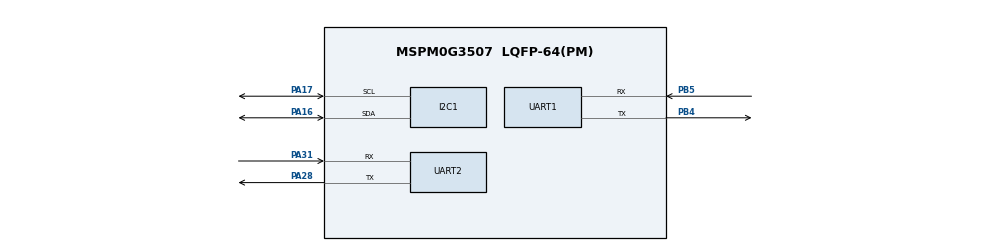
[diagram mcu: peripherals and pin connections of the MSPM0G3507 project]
/**
 * These arguments were used when this file was generated. They will be automatically applied on subsequent loads
 * via the GUI or CLI. Run CLI with '--help' for additional information on how to override these arguments.
 * @cliArgs --device "MSPM0G350X" --part "Default" --package "LQFP-64(PM)" --product "mspm0_sdk@2.05.01.00"
 * @v2CliArgs --device "MSPM0G3507" --package "LQFP-64(PM)" --product "mspm0_sdk@2.05.01.00"
 * @versions {"tool":"1.24.1+4189"}
 */

/**
 * Import the modules used in this configuration.
 */
const I2C     = scripting.addModule("/ti/driverlib/I2C", {}, false);
const I2C1    = I2C.addInstance();
const SYSCTL  = scripting.addModule("/ti/driverlib/SYSCTL");
const SYSTICK = scripting.addModule("/ti/driverlib/SYSTICK");
const TIMER   = scripting.addModule("/ti/driverlib/TIMER", {}, false);
const TIMER1  = TIMER.addInstance();
const UART    = scripting.addModule("/ti/driverlib/UART", {}, false);
const UART1   = UART.addInstance();
const UART2   = UART.addInstance();

/**
 * Write custom configuration values to the imported modules.
 */
const gate7  = system.clockTree["MFCLKGATE"];
gate7.enable = true;

I2C1.$name                           = "I2C_0";
I2C1.basicEnableController           = true;
I2C1.basicControllerStandardBusSpeed = "Fast";
I2C1.peripheral.sdaPin.$assign       = "PA16";
I2C1.peripheral.sclPin.$assign       = "PA17";
I2C1.sdaPinConfig.$name              = "ti_driverlib_gpio_GPIOPinGeneric4";
I2C1.sclPinConfig.$name              = "ti_driverlib_gpio_GPIOPinGeneric5";

const Board = scripting.addModule("/ti/driverlib/Board", {}, false);

SYSCTL.forceDefaultClkConfig = true;
SYSCTL.clockTreeEn           = true;

SYSTICK.periodEnable      = true;
SYSTICK.period            = 32000;
SYSTICK.interruptEnable   = true;
SYSTICK.interruptPriority = "0";
SYSTICK.systickEnable     = true;

TIMER1.$name              = "TIMER_gimbal";
TIMER1.timerClkDiv        = 8;
TIMER1.timerClkPrescale   = 100;
TIMER1.timerMode          = "PERIODIC";
TIMER1.timerPeriod        = "0.005";
TIMER1.timerStartTimer    = true;
TIMER1.interrupts         = ["ZERO"];
TIMER1.peripheral.$assign = "TIMA1";

UART1.$name                            = "UART_1";
UART1.uartClkSrc                       = "MFCLK";
UART1.targetBaudRate                   = 115200;
UART1.enabledInterrupts                = ["RX","TX"];
UART1.peripheral.$assign               = "UART1";
UART1.peripheral.rxPin.$assign         = "PB5";
UART1.peripheral.txPin.$assign         = "PB4";
UART1.txPinConfig.$name                = "ti_driverlib_gpio_GPIOPinGeneric0";
UART1.txPinConfig.direction            = scripting.forceWrite("OUTPUT");
UART1.txPinConfig.hideOutputInversion  = scripting.forceWrite(false);
UART1.txPinConfig.onlyInternalResistor = scripting.forceWrite(false);
UART1.txPinConfig.passedPeripheralType = scripting.forceWrite("Digital");
UART1.rxPinConfig.$name                = "ti_driverlib_gpio_GPIOPinGeneric1";
UART1.rxPinConfig.hideOutputInversion  = scripting.forceWrite(false);
UART1.rxPinConfig.onlyInternalResistor = scripting.forceWrite(false);
UART1.rxPinConfig.passedPeripheralType = scripting.forceWrite("Digital");

UART2.$name                            = "UART_0";
UART2.uartClkSrc                       = "MFCLK";
UART2.targetBaudRate                   = 115200;
UART2.enabledInterrupts                = ["RX","TX"];
UART2.peripheral.rxPin.$assign         = "PA31";
UART2.peripheral.txPin.$assign         = "PA28";
UART2.txPinConfig.$name                = "ti_driverlib_gpio_GPIOPinGeneric2";
UART2.txPinConfig.direction            = scripting.forceWrite("OUTPUT");
UART2.txPinConfig.hideOutputInversion  = scripting.forceWrite(false);
UART2.txPinConfig.onlyInternalResistor = scripting.forceWrite(false);
UART2.txPinConfig.passedPeripheralType = scripting.forceWrite("Digital");
UART2.rxPinConfig.$name                = "ti_driverlib_gpio_GPIOPinGeneric3";
UART2.rxPinConfig.hideOutputInversion  = scripting.forceWrite(false);
UART2.rxPinConfig.onlyInternalResistor = scripting.forceWrite(false);
UART2.rxPinConfig.passedPeripheralType = scripting.forceWrite("Digital");

/**
 * Pinmux solution for unlocked pins/peripherals. This ensures that minor changes to the automatic solver in a future
 * version of the tool will not impact the pinmux you originally saw.  These lines can be completely deleted in order to
 * re-solve from scratch.
 */
I2C1.peripheral.$suggestSolution           = "I2C1";
Board.peripheral.$suggestSolution          = "DEBUGSS";
Board.peripheral.swclkPin.$suggestSolution = "PA20";
Board.peripheral.swdioPin.$suggestSolution = "PA19";
UART2.peripheral.$suggestSolution          = "UART0";
